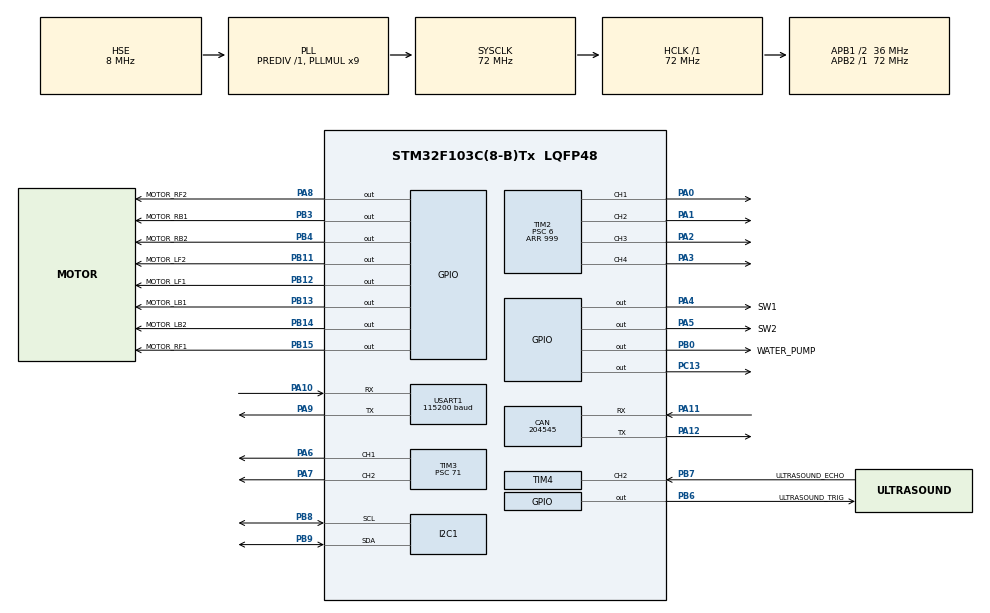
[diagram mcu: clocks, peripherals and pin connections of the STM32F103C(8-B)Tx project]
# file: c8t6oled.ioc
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CAN.BS1=CAN_BS1_8TQ
CAN.BS2=CAN_BS2_2TQ
CAN.CalculateBaudRate=204545
CAN.CalculateTimeBit=4888
CAN.CalculateTimeQuantum=444.44444444444446
Mcu.Family=STM32F1
Mcu.Name=STM32F103C(8-B)Tx
Mcu.Package=LQFP48
NVIC.CAN1_RX1_IRQn=true\:0\:0\:false\:false\:true\:true\:true\:true
NVIC.PriorityGroup=NVIC_PRIORITYGROUP_4
NVIC.TIM2_IRQn=true\:2\:0\:true\:false\:true\:true\:true\:true
NVIC.TIM4_IRQn=true\:2\:0\:true\:false\:true\:true\:true\:true
NVIC.USART1_IRQn=true\:1\:0\:true\:false\:true\:true\:true\:true
PA0-WKUP.Signal=S_TIM2_CH1_ETR
PA1.Signal=S_TIM2_CH2
PA10.Mode=Asynchronous
PA10.Signal=USART1_RX
PA11.Mode=CAN_Activate
PA11.Signal=CAN_RX
PA12.Mode=CAN_Activate
PA12.Signal=CAN_TX
PA13.Mode=Serial_Wire
PA13.Signal=SYS_JTMS-SWDIO
PA14.Mode=Serial_Wire
PA14.Signal=SYS_JTCK-SWCLK
PA2.Signal=S_TIM2_CH3
PA3.Signal=S_TIM2_CH4
PA4.GPIO_Label=SW1
PA4.GPIO_ModeDefaultOutputPP=GPIO_MODE_OUTPUT_OD
PA4.GPIO_PuPd=GPIO_NOPULL
PA4.PinState=GPIO_PIN_SET
PA4.Signal=GPIO_Output
PA5.GPIO_Label=SW2
PA5.GPIO_ModeDefaultOutputPP=GPIO_MODE_OUTPUT_OD
PA5.GPIO_PuPd=GPIO_NOPULL
PA5.PinState=GPIO_PIN_SET
PA5.Signal=GPIO_Output
PA6.Signal=S_TIM3_CH1
PA7.Signal=S_TIM3_CH2
PA8.GPIO_Label=MOTOR_RF2
PA8.Signal=GPIO_Output
PA9.Mode=Asynchronous
PA9.Signal=USART1_TX
PB0.GPIO_Label=WATER_PUMP
PB0.GPIO_ModeDefaultOutputPP=GPIO_MODE_OUTPUT_PP
PB0.GPIO_PuPd=GPIO_NOPULL
PB0.PinState=GPIO_PIN_RESET
PB0.Signal=GPIO_Output
PB11.GPIO_Label=MOTOR_LF2
PB11.Signal=GPIO_Output
PB12.GPIO_Label=MOTOR_LF1
PB12.Signal=GPIO_Output
PB13.GPIO_Label=MOTOR_LB1
PB13.Signal=GPIO_Output
PB14.GPIO_Label=MOTOR_LB2
PB14.Signal=GPIO_Output
PB15.GPIO_Label=MOTOR_RF1
PB15.Signal=GPIO_Output
PB3.GPIO_Label=MOTOR_RB1
PB3.Signal=GPIO_Output
PB4.GPIO_Label=MOTOR_RB2
PB4.Signal=GPIO_Output
PB6.GPIO_Label=ULTRASOUND_TRIG
PB6.GPIO_ModeDefaultOutputPP=GPIO_MODE_OUTPUT_PP
PB6.GPIO_PuPd=GPIO_NOPULL
PB6.PinState=GPIO_PIN_RESET
PB6.Signal=GPIO_Output
PB7.GPIO_Label=ULTRASOUND_ECHO
PB7.Signal=S_TIM4_CH2
PB8.Mode=I2C
PB8.Signal=I2C1_SCL
PB9.Mode=I2C
PB9.Signal=I2C1_SDA
PC13-TAMPER-RTC.Signal=GPIO_Output
PC14-OSC32_IN.Mode=LSE-External-Oscillator
PC14-OSC32_IN.Signal=RCC_OSC32_IN
PC15-OSC32_OUT.Mode=LSE-External-Oscillator
PC15-OSC32_OUT.Signal=RCC_OSC32_OUT
PD0-OSC_IN.Mode=HSE-External-Oscillator
PD0-OSC_IN.Signal=RCC_OSC_IN
PD1-OSC_OUT.Mode=HSE-External-Oscillator
PD1-OSC_OUT.Signal=RCC_OSC_OUT
ProjectManager.HeapSize=0x200
ProjectManager.StackSize=0x400
ProjectManager.TargetToolchain=MDK-ARM V5.32
RCC.AHBFreq_Value=72000000
RCC.APB1CLKDivider=RCC_HCLK_DIV2
RCC.APB1Freq_Value=36000000
RCC.APB1TimFreq_Value=72000000
RCC.APB2Freq_Value=72000000
RCC.APB2TimFreq_Value=72000000
RCC.HCLKFreq_Value=72000000
RCC.PLLMUL=RCC_PLL_MUL9
RCC.PLLSourceVirtual=RCC_PLLSOURCE_HSE
RCC.SYSCLKFreq_VALUE=72000000
RCC.SYSCLKSource=RCC_SYSCLKSOURCE_PLLCLK
RCC.USBFreq_Value=72000000
SH.S_TIM2_CH1_ETR.0=TIM2_CH1,PWM Generation1 CH1
SH.S_TIM2_CH2.0=TIM2_CH2,PWM Generation2 CH2
SH.S_TIM2_CH3.0=TIM2_CH3,PWM Generation3 CH3
SH.S_TIM2_CH4.0=TIM2_CH4,PWM Generation4 CH4
SH.S_TIM3_CH1.0=TIM3_CH1,PWM Generation1 CH1
SH.S_TIM3_CH2.0=TIM3_CH2,PWM Generation2 CH2
SH.S_TIM4_CH2.0=TIM4_CH2,Input_Capture2_from_TI2
TIM2.Channel-PWM\ Generation1\ CH1=TIM_CHANNEL_1
TIM2.Channel-PWM\ Generation2\ CH2=TIM_CHANNEL_2
TIM2.Channel-PWM\ Generation3\ CH3=TIM_CHANNEL_3
TIM2.Channel-PWM\ Generation4\ CH4=TIM_CHANNEL_4
TIM2.Period=999
TIM2.Prescaler=6
TIM3.Channel-PWM\ Generation1\ CH1=TIM_CHANNEL_1
TIM3.Channel-PWM\ Generation2\ CH2=TIM_CHANNEL_2
TIM3.Period=20000-1
TIM3.Prescaler=71
TIM4.Channel-Input_Capture2_from_TI2=TIM_CHANNEL_2
TIM4.Period=65535
TIM4.Prescaler=71
USART1.BaudRate=115200
USART1.VirtualMode=VM_ASYNC
board=custom

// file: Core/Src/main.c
/* USER CODE BEGIN Header */
/**
  ******************************************************************************
  * @file           : main.c
  * @brief          : Main program body
  ******************************************************************************
  * @attention
  *
  * Copyright (c) 2025 STMicroelectronics.
  * All rights reserved.
  *
  * This software is licensed under terms that can be found in the LICENSE file
  * in the root directory of this software component.
  * If no LICENSE file comes with this software, it is provided AS-IS.
  *
  ******************************************************************************
  */
/* USER CODE END Header */
#include "main.h"
#include "can.h"
#include "i2c.h"
#include "tim.h"
#include "usart.h"
#include "gpio.h"

/* USER CODE BEGIN Includes */
#include "hardware.h"
/* USER CODE END Includes */

void SystemClock_Config(void);

int main(void)
{

  /* MCU Configuration--------------------------------------------------------*/

  /* Reset of all peripherals, Initializes the Flash interface and the Systick. */
  HAL_Init();

  /* Configure the system clock */
  SystemClock_Config();

  /* Initialize all configured peripherals */
  MX_GPIO_Init();
  MX_TIM2_Init();
  MX_USART1_UART_Init();
  MX_TIM3_Init();
  MX_TIM4_Init();
  MX_I2C1_Init();
  MX_CAN_Init();
  /* USER CODE BEGIN 2 */
  HAL_Delay(1000);
	State_Machine_Init();

  /* USER CODE END 2 */

  /* Infinite loop */
  /* USER CODE BEGIN WHILE */
  while (1)
  {
		State_Machine_Update();

  }
    /* USER CODE END WHILE */

}

void SystemClock_Config(void)
{
  RCC_OscInitTypeDef RCC_OscInitStruct = {0};
  RCC_ClkInitTypeDef RCC_ClkInitStruct = {0};

  /** Initializes the RCC Oscillators according to the specified parameters
  * in the RCC_OscInitTypeDef structure.
  */
  RCC_OscInitStruct.OscillatorType = RCC_OSCILLATORTYPE_HSE;
  RCC_OscInitStruct.HSEState = RCC_HSE_ON;
  RCC_OscInitStruct.HSEPredivValue = RCC_HSE_PREDIV_DIV1;
  RCC_OscInitStruct.HSIState = RCC_HSI_ON;
  RCC_OscInitStruct.PLL.PLLState = RCC_PLL_ON;
  RCC_OscInitStruct.PLL.PLLSource = RCC_PLLSOURCE_HSE;
  RCC_OscInitStruct.PLL.PLLMUL = RCC_PLL_MUL9;
  if (HAL_RCC_OscConfig(&RCC_OscInitStruct) != HAL_OK)
  {
    Error_Handler();
  }

  /** Initializes the CPU, AHB and APB buses clocks
  */
  RCC_ClkInitStruct.ClockType = RCC_CLOCKTYPE_HCLK|RCC_CLOCKTYPE_SYSCLK
                              |RCC_CLOCKTYPE_PCLK1|RCC_CLOCKTYPE_PCLK2;
  RCC_ClkInitStruct.SYSCLKSource = RCC_SYSCLKSOURCE_PLLCLK;
  RCC_ClkInitStruct.AHBCLKDivider = RCC_SYSCLK_DIV1;
  RCC_ClkInitStruct.APB1CLKDivider = RCC_HCLK_DIV2;
  RCC_ClkInitStruct.APB2CLKDivider = RCC_HCLK_DIV1;

  if (HAL_RCC_ClockConfig(&RCC_ClkInitStruct, FLASH_LATENCY_2) != HAL_OK)
  {
    Error_Handler();
  }
}

void Error_Handler(void)
{
  __disable_irq();
  while (1)
  {
  }
}
#ifdef USE_FULL_ASSERT
/**
  * @brief  Reports the name of the source file and the source line number
  *         where the assert_param error has occurred.
  * @param  file: pointer to the source file name
  * @param  line: assert_param error line source number
  * @retval None
  */
void assert_failed(uint8_t *file, uint32_t line)
{
  /* USER CODE BEGIN 6 */
  (void)file;
  (void)line;
  while (1);
  /* USER CODE END 6 */
}
#endif /* USE_FULL_ASSERT */
